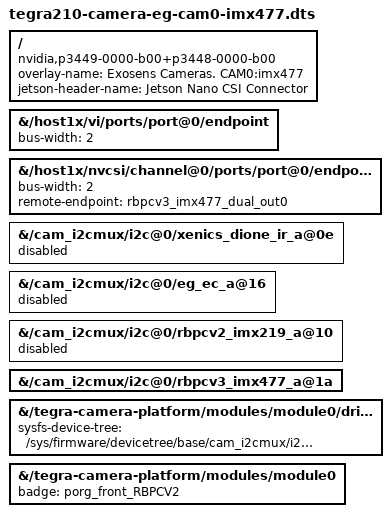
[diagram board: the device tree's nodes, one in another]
// SPDX-License-Identifier: GPL-2.0-only

/dts-v1/;
/plugin/;

/ {
	overlay-name = "Exosens Cameras. CAM0:imx477";
	jetson-header-name = "Jetson Nano CSI Connector";
	compatible = "nvidia,p3449-0000-b00+p3448-0000-b00", "nvidia,p3449-0000-b00+p3448-0002-b00";

	fragment@10 {
		target-path = "/host1x/vi/ports/port@0/endpoint";
		__overlay__ {
			bus-width=<2>;
		};
	};

	fragment@11 {
		target-path = "/host1x/nvcsi/channel@0/ports/port@0/endpoint@0";
		__overlay__ {
			bus-width=<2>;
         remote-endpoint = <&rbpcv3_imx477_dual_out0>;
		};
	};

   // Disable Dione cameras
	fragment@12 {
		target-path = "/cam_i2cmux/i2c@0/xenics_dione_ir_a@0e";
		__overlay__ {
         status = "disabled";
		};
	};

   // Disable EngineCore cameras
	fragment@13 {
		target-path = "/cam_i2cmux/i2c@0/eg_ec_a@16";
		__overlay__ {
         status = "disabled";
		};
	};

  // Disable other cameras 
	fragment@30 {
		target-path = "/cam_i2cmux/i2c@0/rbpcv2_imx219_a@10";
		__overlay__ {
         status = "disabled";
		};
	};

	// Enable imx477
	fragment@31 {
		target-path = "/cam_i2cmux/i2c@0/rbpcv3_imx477_a@1a";
		__overlay__ {
         status = "okay";
		};
	};

	fragment@32 {
		target-path = "/tegra-camera-platform/modules/module0/drivernode0";
		__overlay__ {
			sysfs-device-tree = "/sys/firmware/devicetree/base/cam_i2cmux/i2c@0/rbpcv3_imx477_a@1a";
		};
	};

	fragment@33 {
		target-path = "/tegra-camera-platform/modules/module0";
		__overlay__ {
			badge = "porg_front_RBPCV2";
		};
	};

};
